# Qorvo_SVD register map
Vendor: Qorvo Inc; Series: ARMCM4; File version: 1.0
Registers are 8-bit, read-write, reset 0x0 unless marked. A register's access mark holds for its fields unless they carry their own. Offsets are from the block's base; [hi:lo] are bit positions.

## I2C_M
Base 0x40001020
0x00 I2C_M_PRESCALER 16-bit reset 0xFFFF
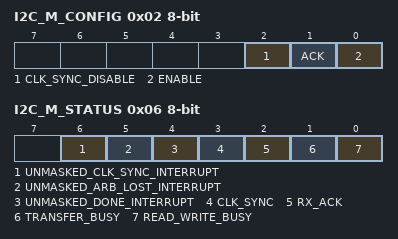
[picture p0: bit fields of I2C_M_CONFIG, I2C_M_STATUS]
0x02 I2C_M_CONFIG
  [2] CLK_SYNC_DISABLE — Disable clock synchronization slave wait detection
  [1] ACK — ACK to be transmitted
  [0] ENABLE — Enable core when '1' : en has to be put to '0' when a new prescaler value is loaded
0x03 I2C_M_TX_DATA
  [7:0] TX_DATA — Byte to be transferred
0x04 I2C_M_RX_DATA ro
  [7:0] RX_DATA — Byte received
0x06 I2C_M_STATUS ro
  [6] UNMASKED_CLK_SYNC_INTERRUPT — Unmasked Clock Synchronization Slave Wait Interrupt
  [5] UNMASKED_ARB_LOST_INTERRUPT — Unmasked Arbitration Lost Interrupt
  [4] UNMASKED_DONE_INTERRUPT
  [3] CLK_SYNC — Clock Synchornization Slave Wait
  [2] RX_ACK — ACK from slave received
  [1] TRANSFER_BUSY — Data Transfer in progress (between start and stop condition)
  [0] READ_WRITE_BUSY — Byte Read or Byte Write in progress

## SSP
Base 0x40001080
0x00 SSP_A_PTR[0]
  [7:0] A_PTR[0] — Authentication pointer
0x01 SSP_A_PTR[1]
  [7:0] A_PTR[1] — Authentication pointer
0x02 SSP_A_PTR[2]
  [6:0] A_PTR[2] — Authentication pointer
0x03 SSP_A_LEN
  [7:0] A_LEN — Authentication length
0x04 SSP_MSG_PTR[0]
  [7:0] MSG_PTR[0] — Message in pointer
0x05 SSP_MSG_PTR[1]
  [7:0] MSG_PTR[1] — Message in pointer
0x06 SSP_MSG_PTR[2]
  [6:0] MSG_PTR[2] — Message in pointer
0x07 SSP_MSG_LEN
  [7:0] MSG_LEN — Message length
0x08 SSP_MIC_PTR[0]
  [7:0] MIC_PTR[0] — Mic pointer
0x09 SSP_MIC_PTR[1]
  [7:0] MIC_PTR[1] — Mic pointer
0x0A SSP_MIC_PTR[2]
  [6:0] MIC_PTR[2] — Mic pointer
0x0C SSP_KEY_PTR[0]
  [7:0] KEY_PTR[0] — key pointer - for access to secured keys, key pointer has to be a multiple of 16 bytes
0x0D SSP_KEY_PTR[1]
  [7:0] KEY_PTR[1] — key pointer - for access to secured keys, key pointer has to be a multiple of 16 bytes
0x0E SSP_KEY_PTR[2]
  [6:0] KEY_PTR[2] — key pointer - for access to secured keys, key pointer has to be a multiple of 16 bytes
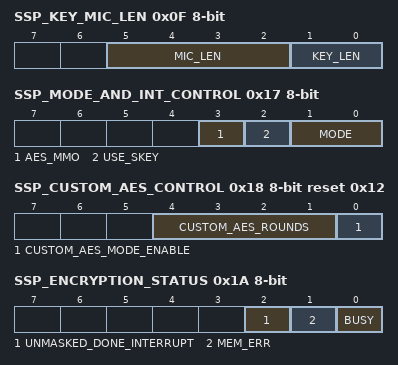
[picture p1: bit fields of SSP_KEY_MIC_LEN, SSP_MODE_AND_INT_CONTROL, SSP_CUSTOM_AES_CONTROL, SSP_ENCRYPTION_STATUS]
0x0F SSP_KEY_MIC_LEN
  [5:2] MIC_LEN — Mic length/2 (actual length is the value set by this property multiplied by 2)
  [1:0] KEY_LEN — key length enumerate : "00" = 128 bit key, "01" = 192 bit key, "10" = 256 bit key
0x10 SSP_MSG_OUT_PTR[0]
  [7:0] MSG_OUT_PTR[0] — Pointer to destination location for encrypted data
0x11 SSP_MSG_OUT_PTR[1]
  [7:0] MSG_OUT_PTR[1] — Pointer to destination location for encrypted data
0x12 SSP_MSG_OUT_PTR[2]
  [6:0] MSG_OUT_PTR[2] — Pointer to destination location for encrypted data
0x14 SSP_NONCE_PTR[0]
  [7:0] NONCE_PTR[0] — Pointer to destination location for encrypted data
0x15 SSP_NONCE_PTR[1]
  [7:0] NONCE_PTR[1] — Pointer to destination location for encrypted data
0x16 SSP_NONCE_PTR[2]
  [6:0] NONCE_PTR[2] — Pointer to destination location for encrypted data
0x17 SSP_MODE_AND_INT_CONTROL
  [3] AES_MMO — when set the engine is set into aes_mmo mode - only affects aes_mode
  [2] USE_SKEY — uses internal secret key when '1'
  [1:0] MODE — "00" = Encryption, "01" = decryption, "10" = aes mode, "11" = reserved
0x18 SSP_CUSTOM_AES_CONTROL reset 0x12
  [4:1] CUSTOM_AES_ROUNDS — standard value for key_len 128 = 9, kay_len 192 = 10, key_len 256 = 12. When set differently, aes operation will be non-standard
  [0] CUSTOM_AES_MODE_ENABLE — enables to override the standard aes sequence and define the number of rounds. When enabled, secure key access is disabled
0x1A SSP_ENCRYPTION_STATUS ro
  [2] UNMASKED_DONE_INTERRUPT — Unmasked interrupt indicating encryption cycle finished
  [1] MEM_ERR — Set when an error occurred while accessing the memory
  [0] BUSY — Indicates the encryption cycle is running

## UART_0
Base 0x400010A0
0x04 UART_0_BAUD_RATE 16-bit reset 0x22
  [11:0] BAUD_RATE — Actual baud rate = 16MHz / 8*(baud_rate+1)
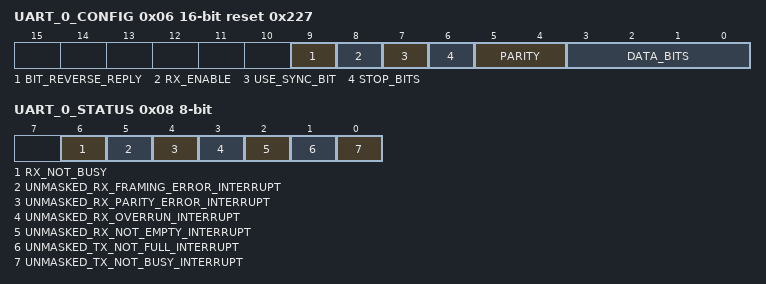
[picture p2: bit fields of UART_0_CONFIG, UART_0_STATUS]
0x06 UART_0_CONFIG 16-bit reset 0x227
  [9] BIT_REVERSE_REPLY — In case of the HW MSI interface (stream_to_regmap = 0), bit_reverse the data part of the reply. This feature was added for Lime.
  [8] RX_ENABLE — Enable the UART receiver. (Note the transmitter is automatically enabled when loading data into tx_data)
  [7] USE_SYNC_BIT — In case of the HW MSI interface (stream_to_regmap = 0), interpret bit 8 as sync bit to reset internal logic.
  [6] STOP_BITS — Number of stop bits - 1 (0x0 = 1, 0x1 = 2. For RX only the first one is checked)
  [5:4] PARITY — Parity bit mode. Controls both the generation for TX and the check for RX.
  [3:0] DATA_BITS — Number of data bits in an SPI frame - 1 (0x7 = one byte)
0x08 UART_0_STATUS ro
  [6] RX_NOT_BUSY — Status flag for UART RX not busy. Active when no RX transfer is ongoing.
  [5] UNMASKED_RX_FRAMING_ERROR_INTERRUPT — Event and unmasked interrupt flag for the occurrence of a rx framing error. Set when the (first) stop bit of a received frame was not 1. Cleared explicitly by the SW.
  [4] UNMASKED_RX_PARITY_ERROR_INTERRUPT — Event and unmasked interrupt flag for the occurrence of a rx parity error. Set when the parity checking is enabled and the received parity bit does not match with the calculated. Cleared explicitly by the SW.
  [3] UNMASKED_RX_OVERRUN_INTERRUPT — Event and unmasked interrupt flag for the occurrence of a rx data buffer overrun event. Set when the rx data buffer is full and new rx data is available. Cleared explicitly by the SW.
  [2] UNMASKED_RX_NOT_EMPTY_INTERRUPT — Status and unmasked interrupt flag for RX buffer not empty. The interrupt is cleared implicitly when reading the last RX data from the buffer.
  [1] UNMASKED_TX_NOT_FULL_INTERRUPT — Status and unmasked interrupt flag for TX buffer not full. The interrupt is cleared implicitly when writing new TX data fills the buffer.
  [0] UNMASKED_TX_NOT_BUSY_INTERRUPT — Status and unmasked interrupt flag for UART TX not busy. The interrupt is cleared implicitly when writing new TX data. Active when no TX transfer ongoing and no data in TX buffer.

## UART_1
Base 0x400010B0
Registers as UART_0 (with UART_0 read as UART_1).
